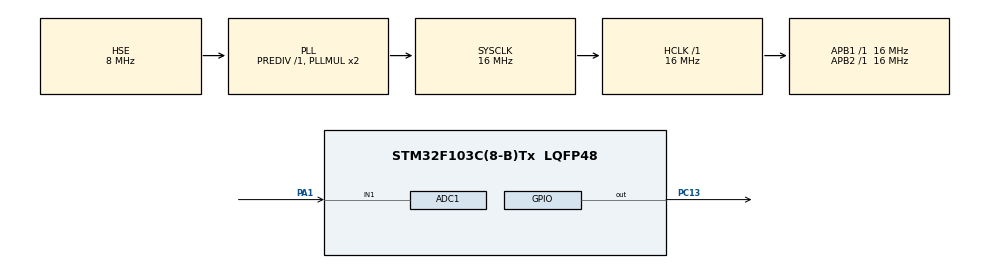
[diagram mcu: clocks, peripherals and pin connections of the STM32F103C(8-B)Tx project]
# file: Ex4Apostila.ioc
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ADC1.Channel-0\#ChannelRegularConversion=ADC_CHANNEL_1
ADC1.NbrOfConversionFlag=1
ADC1.Rank-0\#ChannelRegularConversion=1
ADC1.SamplingTime-0\#ChannelRegularConversion=ADC_SAMPLETIME_1CYCLE_5
ADC1.master=1
Mcu.Family=STM32F1
Mcu.Name=STM32F103C(8-B)Tx
Mcu.Package=LQFP48
NVIC.PriorityGroup=NVIC_PRIORITYGROUP_4
NVIC.TIM2_IRQn=true\:0\:0\:false\:false\:true\:true\:true\:true
PA1.Signal=ADCx_IN1
PA13.Mode=Serial_Wire
PA13.Signal=SYS_JTMS-SWDIO
PA14.Mode=Serial_Wire
PA14.Signal=SYS_JTCK-SWCLK
PC13-TAMPER-RTC.Signal=GPIO_Output
PD0-OSC_IN.Mode=HSE-External-Oscillator
PD0-OSC_IN.Signal=RCC_OSC_IN
PD1-OSC_OUT.Mode=HSE-External-Oscillator
PD1-OSC_OUT.Signal=RCC_OSC_OUT
ProjectManager.HeapSize=0x200
ProjectManager.StackSize=0x400
ProjectManager.TargetToolchain=STM32CubeIDE
RCC.AHBFreq_Value=16000000
RCC.APB1Freq_Value=16000000
RCC.APB1TimFreq_Value=16000000
RCC.APB2Freq_Value=16000000
RCC.APB2TimFreq_Value=16000000
RCC.HCLKFreq_Value=16000000
RCC.PLLSourceVirtual=RCC_PLLSOURCE_HSE
RCC.SYSCLKFreq_VALUE=16000000
RCC.SYSCLKSource=RCC_SYSCLKSOURCE_PLLCLK
RCC.USBFreq_Value=16000000
SH.ADCx_IN1.0=ADC1_IN1,IN1
TIM2.Period=1999
TIM2.Prescaler=15999
VP_TIM2_VS_ClockSourceINT.Mode=Internal
board=custom

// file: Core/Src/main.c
/* USER CODE BEGIN Header */
/**
  ******************************************************************************
  * @file           : main.c
  * @brief          : Main program body
  ******************************************************************************
  * @attention
  *
  * Copyright (c) 2022 STMicroelectronics.
  * All rights reserved.
  *
  * This software is licensed under terms that can be found in the LICENSE file
  * in the root directory of this software component.
  * If no LICENSE file comes with this software, it is provided AS-IS.
  *
  ******************************************************************************
  */
/* USER CODE END Header */
#include "main.h"

ADC_HandleTypeDef hadc1;

TIM_HandleTypeDef htim2;

/* USER CODE BEGIN PV */
int ADC_result = 0;
/* USER CODE END PV */

void SystemClock_Config(void);
static void MX_GPIO_Init(void);
static void MX_TIM2_Init(void);
static void MX_ADC1_Init(void);

int main(void)
{

  /* MCU Configuration--------------------------------------------------------*/

  /* Reset of all peripherals, Initializes the Flash interface and the Systick. */
  HAL_Init();

  /* Configure the system clock */
  SystemClock_Config();

  /* Initialize all configured peripherals */
  MX_GPIO_Init();
  MX_TIM2_Init();
  MX_ADC1_Init();
  /* USER CODE BEGIN 2 */
  HAL_TIM_Base_Start_IT(&htim2);
  /* USER CODE END 2 */

  /* Infinite loop */
  /* USER CODE BEGIN WHILE */
  while (1)
  {
	  HAL_ADC_Start(&hadc1);
	  HAL_ADC_PollForConversion(&hadc1, 100);
	  ADC_result = HAL_ADC_GetValue(&hadc1);
	  HAL_ADC_Stop(&hadc1);
    /* USER CODE END WHILE */

  }
}

void SystemClock_Config(void)
{
  RCC_OscInitTypeDef RCC_OscInitStruct = {0};
  RCC_ClkInitTypeDef RCC_ClkInitStruct = {0};
  RCC_PeriphCLKInitTypeDef PeriphClkInit = {0};

  /** Initializes the RCC Oscillators according to the specified parameters
  * in the RCC_OscInitTypeDef structure.
  */
  RCC_OscInitStruct.OscillatorType = RCC_OSCILLATORTYPE_HSE;
  RCC_OscInitStruct.HSEState = RCC_HSE_ON;
  RCC_OscInitStruct.HSEPredivValue = RCC_HSE_PREDIV_DIV1;
  RCC_OscInitStruct.HSIState = RCC_HSI_ON;
  RCC_OscInitStruct.PLL.PLLState = RCC_PLL_ON;
  RCC_OscInitStruct.PLL.PLLSource = RCC_PLLSOURCE_HSE;
  RCC_OscInitStruct.PLL.PLLMUL = RCC_PLL_MUL2;
  if (HAL_RCC_OscConfig(&RCC_OscInitStruct) != HAL_OK)
  {
    Error_Handler();
  }

  /** Initializes the CPU, AHB and APB buses clocks
  */
  RCC_ClkInitStruct.ClockType = RCC_CLOCKTYPE_HCLK|RCC_CLOCKTYPE_SYSCLK
                              |RCC_CLOCKTYPE_PCLK1|RCC_CLOCKTYPE_PCLK2;
  RCC_ClkInitStruct.SYSCLKSource = RCC_SYSCLKSOURCE_PLLCLK;
  RCC_ClkInitStruct.AHBCLKDivider = RCC_SYSCLK_DIV1;
  RCC_ClkInitStruct.APB1CLKDivider = RCC_HCLK_DIV1;
  RCC_ClkInitStruct.APB2CLKDivider = RCC_HCLK_DIV1;

  if (HAL_RCC_ClockConfig(&RCC_ClkInitStruct, FLASH_LATENCY_0) != HAL_OK)
  {
    Error_Handler();
  }
  PeriphClkInit.PeriphClockSelection = RCC_PERIPHCLK_ADC;
  PeriphClkInit.AdcClockSelection = RCC_ADCPCLK2_DIV2;
  if (HAL_RCCEx_PeriphCLKConfig(&PeriphClkInit) != HAL_OK)
  {
    Error_Handler();
  }
}

static void MX_ADC1_Init(void)
{

  ADC_ChannelConfTypeDef sConfig = {0};

  /** Common config
  */
  hadc1.Instance = ADC1;
  hadc1.Init.ScanConvMode = ADC_SCAN_DISABLE;
  hadc1.Init.ContinuousConvMode = DISABLE;
  hadc1.Init.DiscontinuousConvMode = DISABLE;
  hadc1.Init.ExternalTrigConv = ADC_SOFTWARE_START;
  hadc1.Init.DataAlign = ADC_DATAALIGN_RIGHT;
  hadc1.Init.NbrOfConversion = 1;
  if (HAL_ADC_Init(&hadc1) != HAL_OK)
  {
    Error_Handler();
  }

  /** Configure Regular Channel
  */
  sConfig.Channel = ADC_CHANNEL_1;
  sConfig.Rank = ADC_REGULAR_RANK_1;
  sConfig.SamplingTime = ADC_SAMPLETIME_1CYCLE_5;
  if (HAL_ADC_ConfigChannel(&hadc1, &sConfig) != HAL_OK)
  {
    Error_Handler();
  }

}

static void MX_TIM2_Init(void)
{

  TIM_ClockConfigTypeDef sClockSourceConfig = {0};
  TIM_MasterConfigTypeDef sMasterConfig = {0};

  htim2.Instance = TIM2;
  htim2.Init.Prescaler = 15999;
  htim2.Init.CounterMode = TIM_COUNTERMODE_UP;
  htim2.Init.Period = 1999;
  htim2.Init.ClockDivision = TIM_CLOCKDIVISION_DIV1;
  htim2.Init.AutoReloadPreload = TIM_AUTORELOAD_PRELOAD_DISABLE;
  if (HAL_TIM_Base_Init(&htim2) != HAL_OK)
  {
    Error_Handler();
  }
  sClockSourceConfig.ClockSource = TIM_CLOCKSOURCE_INTERNAL;
  if (HAL_TIM_ConfigClockSource(&htim2, &sClockSourceConfig) != HAL_OK)
  {
    Error_Handler();
  }
  sMasterConfig.MasterOutputTrigger = TIM_TRGO_RESET;
  sMasterConfig.MasterSlaveMode = TIM_MASTERSLAVEMODE_DISABLE;
  if (HAL_TIMEx_MasterConfigSynchronization(&htim2, &sMasterConfig) != HAL_OK)
  {
    Error_Handler();
  }

}

static void MX_GPIO_Init(void)
{
  GPIO_InitTypeDef GPIO_InitStruct = {0};

  /* GPIO Ports Clock Enable */
  __HAL_RCC_GPIOC_CLK_ENABLE();
  __HAL_RCC_GPIOD_CLK_ENABLE();
  __HAL_RCC_GPIOA_CLK_ENABLE();

  /*Configure GPIO pin Output Level */
  HAL_GPIO_WritePin(GPIOC, GPIO_PIN_13, GPIO_PIN_RESET);

  /*Configure GPIO pin : PC13 */
  GPIO_InitStruct.Pin = GPIO_PIN_13;
  GPIO_InitStruct.Mode = GPIO_MODE_OUTPUT_PP;
  GPIO_InitStruct.Pull = GPIO_NOPULL;
  GPIO_InitStruct.Speed = GPIO_SPEED_FREQ_LOW;
  HAL_GPIO_Init(GPIOC, &GPIO_InitStruct);

}

void Error_Handler(void)
{
  __disable_irq();
  while (1)
  {
  }
}
